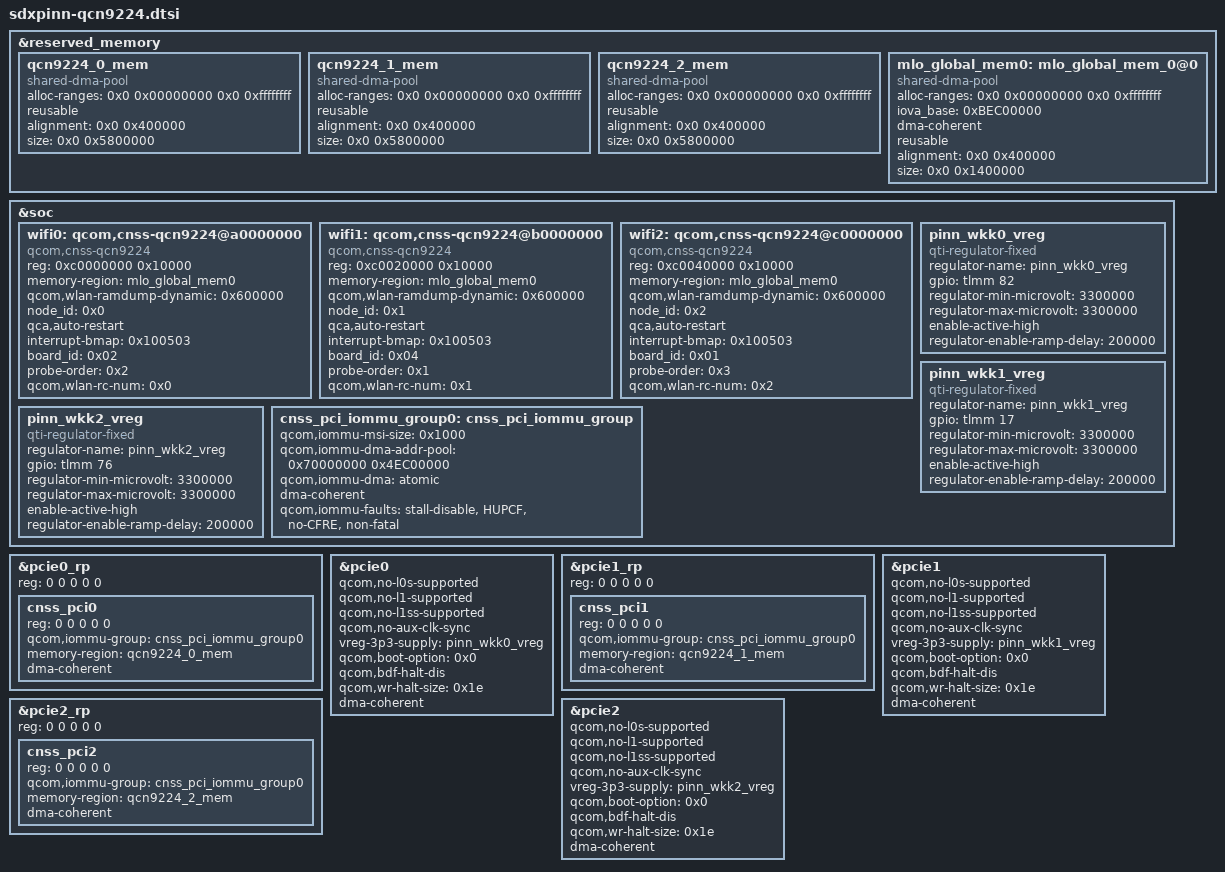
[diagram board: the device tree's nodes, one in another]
&reserved_memory {
	#address-cells = <2>;
	#size-cells = <2>;
	ranges;

	qcn9224_0_mem: qcn9224_0_mem {
		compatible = "shared-dma-pool";
		alloc-ranges = <0x0 0x00000000 0x0 0xffffffff>;
		reusable;
		alignment = <0x0 0x400000>;
		size = <0x0 0x5800000>;
	};

	qcn9224_1_mem: qcn9224_1_mem {
		compatible = "shared-dma-pool";
		alloc-ranges = <0x0 0x00000000 0x0 0xffffffff>;
		reusable;
		alignment = <0x0 0x400000>;
		size = <0x0 0x5800000>;
	};

	qcn9224_2_mem: qcn9224_2_mem {
		compatible = "shared-dma-pool";
		alloc-ranges = <0x0 0x00000000 0x0 0xffffffff>;
		reusable;
		alignment = <0x0 0x400000>;
		size = <0x0 0x5800000>;
	};

	mlo_global_mem0: mlo_global_mem_0@0 {
		compatible = "shared-dma-pool";
		alloc-ranges = <0x0 0x00000000 0x0 0xffffffff>;
		iova_base = <0xBEC00000>;
		dma-coherent;
		reusable;
		alignment = <0x0 0x400000>;
		size = <0x0 0x1400000>;
	};

};

&soc {
	wifi0: qcom,cnss-qcn9224@a0000000 {
			compatible  = "qcom,cnss-qcn9224";
			reg = <0xc0000000 0x10000>;
			reg-names = "smmu_iova_ipa";
			memory-region = <&mlo_global_mem0>;
			qcom,wlan-ramdump-dynamic = <0x600000>;
			node_id = <0x0>;
			qca,auto-restart;
			interrupt-bmap = <0x100503>;
			board_id = <0x02>;
			probe-order = <0x2>;
			qcom,wlan-rc-num = <0x0>;
			status = "ok";
	};

	wifi1: qcom,cnss-qcn9224@b0000000 {
			compatible  = "qcom,cnss-qcn9224";
			reg = <0xc0020000 0x10000>;
			reg-names = "smmu_iova_ipa";
			memory-region = <&mlo_global_mem0>;
			qcom,wlan-ramdump-dynamic = <0x600000>;
			node_id = <0x1>;
			qca,auto-restart;
			interrupt-bmap = <0x100503>;
			board_id = <0x04>;
			probe-order = <0x1>;
			qcom,wlan-rc-num = <0x1>;
			status = "ok";
	};

	wifi2: qcom,cnss-qcn9224@c0000000 {
			compatible  = "qcom,cnss-qcn9224";
			reg = <0xc0040000 0x10000>;
			reg-names = "smmu_iova_ipa";
			memory-region = <&mlo_global_mem0>;
			qcom,wlan-ramdump-dynamic = <0x600000>;
			node_id = <0x2>;
			qca,auto-restart;
			interrupt-bmap = <0x100503>;
			board_id = <0x01>;
			probe-order = <0x3>;
			qcom,wlan-rc-num = <0x2>;
			status = "ok";
	};

	pinn_wkk0_vreg: pinn_wkk0_vreg {
			compatible = "qti-regulator-fixed";
			regulator-name = "pinn_wkk0_vreg";
			gpio = <&tlmm 82 GPIO_ACTIVE_HIGH>;
			regulator-min-microvolt = <3300000>;
			regulator-max-microvolt = <3300000>;
			enable-active-high;
			regulator-enable-ramp-delay = <200000>;
	};

	pinn_wkk1_vreg: pinn_wkk1_vreg {
			compatible = "qti-regulator-fixed";
			regulator-name = "pinn_wkk1_vreg";
			gpio = <&tlmm 17 GPIO_ACTIVE_HIGH>;
			regulator-min-microvolt = <3300000>;
			regulator-max-microvolt = <3300000>;
			enable-active-high;
			regulator-enable-ramp-delay = <200000>;
	};

	pinn_wkk2_vreg: pinn_wkk2_vreg {
			compatible = "qti-regulator-fixed";
			regulator-name = "pinn_wkk2_vreg";
			gpio = <&tlmm 76 GPIO_ACTIVE_HIGH>;
			regulator-min-microvolt = <3300000>;
			regulator-max-microvolt = <3300000>;
			enable-active-high;
			regulator-enable-ramp-delay = <200000>;
	};

	cnss_pci_iommu_group0: cnss_pci_iommu_group {
			qcom,iommu-msi-size = <0x1000>;
			qcom,iommu-dma-addr-pool = <0x70000000 0x4EC00000>;
			qcom,iommu-dma = "atomic";
			dma-coherent;
			qcom,iommu-faults = "stall-disable", "HUPCF", "no-CFRE",
					    "non-fatal";
	};
};

&pcie0_rp {
	reg = <0 0 0 0 0>;
	#address-cells = <5>;
	#size-cells = <0>;
	cnss_pci0: cnss_pci0 {
		reg = <0 0 0 0 0>;
		qcom,iommu-group = <&cnss_pci_iommu_group0>;
		memory-region = <&qcn9224_0_mem>;
		#address-cells = <1>;
		#size-cells = <1>;
		dma-coherent;
	};
};

&pcie0 {
	qcom,no-l0s-supported;
	qcom,no-l1-supported;
	qcom,no-l1ss-supported;
	qcom,no-aux-clk-sync;
	vreg-3p3-supply = <&pinn_wkk0_vreg>;
	qcom,boot-option = <0x0>;
	qcom,bdf-halt-dis;
	qcom,wr-halt-size = <0x1e>;
	dma-coherent;
	status = "ok";
};

&pcie1_rp {
	reg = <0 0 0 0 0>;
	#address-cells = <5>;
	#size-cells = <0>;
	cnss_pci1: cnss_pci1 {
		reg = <0 0 0 0 0>;
		qcom,iommu-group = <&cnss_pci_iommu_group0>;
		memory-region = <&qcn9224_1_mem>;
		#address-cells = <1>;
		#size-cells = <1>;
		dma-coherent;
	};
};

&pcie1 {
	qcom,no-l0s-supported;
	qcom,no-l1-supported;
	qcom,no-l1ss-supported;
	qcom,no-aux-clk-sync;
	vreg-3p3-supply = <&pinn_wkk1_vreg>;
	qcom,boot-option = <0x0>;
	qcom,bdf-halt-dis;
	qcom,wr-halt-size = <0x1e>;
	dma-coherent;
	status = "ok";
};

&pcie2_rp {
	reg = <0 0 0 0 0>;
	#address-cells = <5>;
	#size-cells = <0>;
	cnss_pci2: cnss_pci2 {
		reg = <0 0 0 0 0>;
		qcom,iommu-group = <&cnss_pci_iommu_group0>;
		memory-region = <&qcn9224_2_mem>;
		#address-cells = <1>;
		#size-cells = <1>;
		dma-coherent;
	};
};

&pcie2 {
	qcom,no-l0s-supported;
	qcom,no-l1-supported;
	qcom,no-l1ss-supported;
	qcom,no-aux-clk-sync;
	vreg-3p3-supply = <&pinn_wkk2_vreg>;
	qcom,boot-option = <0x0>;
	qcom,bdf-halt-dis;
	qcom,wr-halt-size = <0x1e>;
	dma-coherent;
	status = "ok";
};


